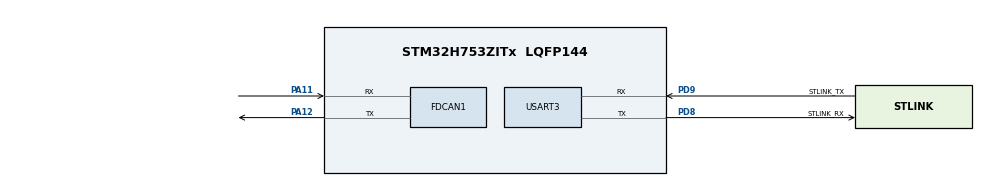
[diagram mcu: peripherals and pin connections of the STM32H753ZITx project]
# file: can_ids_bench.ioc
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CORTEX_M7.CPU_DCache=Enabled
CORTEX_M7.CPU_ICache=Enabled
CORTEX_M7.MPU_Control=MPU_PRIVILEGED_DEFAULT
CORTEX_M7.default_mode_Activation=1
FDCAN1.AutoRetransmission=ENABLE
FDCAN1.CalculateBaudRateNominal=500000
FDCAN1.CalculateTimeBitNominal=2000
FDCAN1.CalculateTimeQuantumNominal=125.0
FDCAN1.Mode=FDCAN_MODE_INTERNAL_LOOPBACK
FDCAN1.NominalPrescaler=1
FDCAN1.NominalSyncJumpWidth=2
FDCAN1.NominalTimeSeg1=13
FDCAN1.NominalTimeSeg2=2
FDCAN1.RxFifo0ElmtsNbr=32
FDCAN1.TxFifoQueueElmtsNbr=8
FDCAN1.TxFifoQueueMode=FDCAN_TX_QUEUE_OPERATION
FREERTOS.Tasks01=defaultTask,24,128,StartDefaultTask,Default,NULL,Dynamic,NULL,NULL
FREERTOS.configTOTAL_HEAP_SIZE=65536
FREERTOS.configUSE_NEWLIB_REENTRANT=1
Mcu.Family=STM32H7
Mcu.Name=STM32H753ZITx
Mcu.Package=LQFP144
NVIC.FDCAN1_IT0_IRQn=true\:5\:0\:true\:false\:true\:true\:true\:true\:true
NVIC.PriorityGroup=NVIC_PRIORITYGROUP_4
NVIC.TIM6_DAC_IRQn=true\:15\:0\:false\:false\:true\:false\:false\:true\:true
NVIC.TIM7_IRQn=true\:5\:0\:false\:false\:true\:true\:true\:true\:true
NVIC.TimeBase=TIM6_DAC_IRQn
NVIC.TimeBaseIP=TIM6
PA11.Mode=FDCAN_Activate
PA11.Signal=FDCAN1_RX
PA12.Mode=FDCAN_Activate
PA12.Signal=FDCAN1_TX
PA13\ (JTMS/SWDIO).Mode=Serial_Wire
PA13\ (JTMS/SWDIO).Signal=DEBUG_JTMS-SWDIO
PA14\ (JTCK/SWCLK).Mode=Serial_Wire
PA14\ (JTCK/SWCLK).Signal=DEBUG_JTCK-SWCLK
PC14-OSC32_IN\ (OSC32_IN).Signal=RCC_OSC32_IN
PC15-OSC32_OUT\ (OSC32_OUT).Signal=RCC_OSC32_OUT
PD8.GPIO_Label=STLINK_RX
PD8.Mode=Asynchronous
PD8.Signal=USART3_TX
PD9.GPIO_Label=STLINK_TX
PD9.Mode=Asynchronous
PD9.Signal=USART3_RX
PH0-OSC_IN\ (PH0).Mode=HSE-External-Clock-Source
PH0-OSC_IN\ (PH0).Signal=RCC_OSC_IN
PH1-OSC_OUT\ (PH1).Signal=RCC_OSC_OUT
ProjectManager.HeapSize=0x1000
ProjectManager.StackSize=0x2000
ProjectManager.TargetToolchain=STM32CubeIDE
RCC.ADCFreq_Value=16125000
RCC.APB1Freq_Value=120000000
RCC.APB2Freq_Value=120000000
RCC.APB3Freq_Value=120000000
RCC.APB4Freq_Value=120000000
RCC.CortexFreq_Value=480000000
RCC.D1PPRE=RCC_APB3_DIV2
RCC.D2PPRE1=RCC_APB1_DIV2
RCC.D2PPRE2=RCC_APB2_DIV2
RCC.D3PPRE=RCC_APB4_DIV2
RCC.DIVM1=1
RCC.DIVN1=120
RCC.DIVQ1=4
RCC.FDCANCLockSelection=RCC_FDCANCLKSOURCE_HSE
RCC.HCLKFreq_Value=240000000
RCC.HPRE=RCC_HCLK_DIV2
RCC.HSE_VALUE=8000000
RCC.PLLFRACN=0
RCC.PLLSourceVirtual=RCC_PLLSOURCE_HSE
RCC.PWR_Regulator_Voltage_Scale=PWR_REGULATOR_VOLTAGE_SCALE0
RCC.SYSCLKFreq_VALUE=480000000
RCC.SYSCLKSource=RCC_SYSCLKSOURCE_PLLCLK
RCC.USBFreq_Value=240000000
TIM7.Period=49
TIM7.Prescaler=239
USART3.VirtualMode-Asynchronous=VM_ASYNC
VP_FREERTOS_VS_CMSIS_V2.Mode=CMSIS_V2
VP_MEMORYMAP_VS_MEMORYMAP.Mode=CurAppReg
VP_SYS_VS_tim6.Mode=TIM6
VP_TIM7_VS_ClockSourceINT.Mode=Enable_Timer
board=NUCLEO-H753ZI

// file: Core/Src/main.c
/* USER CODE BEGIN Header */
/**
  ******************************************************************************
  * @file           : main.c
  * @brief          : Main program body
  ******************************************************************************
  * @attention
  *
  * Copyright (c) 2026 STMicroelectronics.
  * All rights reserved.
  *
  * This software is licensed under terms that can be found in the LICENSE file
  * in the root directory of this software component.
  * If no LICENSE file comes with this software, it is provided AS-IS.
  *
  ******************************************************************************
  */
/* USER CODE END Header */
#include "main.h"
#include "FreeRTOS.h"
#include "cmsis_os2.h"

/* USER CODE BEGIN Includes */
#include "ids_bench.h"   // declares ids_bench_run()
#include "ids_demo.h"
/* USER CODE END Includes */

FDCAN_HandleTypeDef hfdcan1;

TIM_HandleTypeDef htim7;

UART_HandleTypeDef huart3;

/* Definitions for defaultTask */
osThreadId_t defaultTaskHandle;
const osThreadAttr_t defaultTask_attributes = {
  .name = "defaultTask",
  .stack_size = 128 * 4,
  .priority = (osPriority_t) osPriorityNormal,
};
/* USER CODE BEGIN PV */
volatile uint32_t dbg_tim7_ticks = 0;

/* USER CODE END PV */

void SystemClock_Config(void);
static void MPU_Config(void);
static void MX_GPIO_Init(void);
static void MX_FDCAN1_Init(void);
static void MX_TIM7_Init(void);
static void MX_USART3_UART_Init(void);
void StartDefaultTask(void *argument);

int main(void)
{

  /* MPU Configuration--------------------------------------------------------*/
  MPU_Config();

  /* Enable the CPU Cache */

  /* Enable I-Cache---------------------------------------------------------*/
  SCB_EnableICache();

  /* Enable D-Cache---------------------------------------------------------*/
  SCB_EnableDCache();

  /* MCU Configuration--------------------------------------------------------*/

  /* Reset of all peripherals, Initializes the Flash interface and the Systick. */
  HAL_Init();

  /* Configure the system clock */
  SystemClock_Config();

  /* Initialize all configured peripherals */
  MX_GPIO_Init();
  MX_FDCAN1_Init();
  MX_TIM7_Init();
  MX_USART3_UART_Init();
  /* USER CODE BEGIN 2 */

  // Runs the benchmark once (~1 min) before FreeRTOS starts.
  // hfdcan1 = FDCAN1 handle (internal loopback, 500 kbit/s), huart3 = UART to the ST-LINK USB serial port

 ids_bench_run(&hfdcan1, &huart3);
  /* USER CODE END 2 */

  /* Init scheduler */
  osKernelInitialize();

  /* Create the thread(s) */
  /* creation of defaultTask */
  defaultTaskHandle = osThreadNew(StartDefaultTask, NULL, &defaultTask_attributes);

  /* USER CODE BEGIN RTOS_THREADS */
  /* add threads, ... */
  //ids_demo_start(&hfdcan1, &huart3, &htim7);
  /* USER CODE END RTOS_THREADS */

  /* Start scheduler */
  osKernelStart();

  /* We should never get here as control is now taken by the scheduler */

  /* Infinite loop */
  while (1)
  {

  }
}

void SystemClock_Config(void)
{
  RCC_OscInitTypeDef RCC_OscInitStruct = {0};
  RCC_ClkInitTypeDef RCC_ClkInitStruct = {0};

  /** Supply configuration update enable
  */
  HAL_PWREx_ConfigSupply(PWR_LDO_SUPPLY);

  /** Configure the main internal regulator output voltage
  */
  __HAL_PWR_VOLTAGESCALING_CONFIG(PWR_REGULATOR_VOLTAGE_SCALE0);

  while(!__HAL_PWR_GET_FLAG(PWR_FLAG_VOSRDY)) {}

  /** Initializes the RCC Oscillators according to the specified parameters
  * in the RCC_OscInitTypeDef structure.
  */
  RCC_OscInitStruct.OscillatorType = RCC_OSCILLATORTYPE_HSE;
  RCC_OscInitStruct.HSEState = RCC_HSE_BYPASS;
  RCC_OscInitStruct.PLL.PLLState = RCC_PLL_ON;
  RCC_OscInitStruct.PLL.PLLSource = RCC_PLLSOURCE_HSE;
  RCC_OscInitStruct.PLL.PLLM = 1;
  RCC_OscInitStruct.PLL.PLLN = 120;
  RCC_OscInitStruct.PLL.PLLP = 2;
  RCC_OscInitStruct.PLL.PLLQ = 4;
  RCC_OscInitStruct.PLL.PLLR = 2;
  RCC_OscInitStruct.PLL.PLLRGE = RCC_PLL1VCIRANGE_3;
  RCC_OscInitStruct.PLL.PLLVCOSEL = RCC_PLL1VCOWIDE;
  RCC_OscInitStruct.PLL.PLLFRACN = 0;
  if (HAL_RCC_OscConfig(&RCC_OscInitStruct) != HAL_OK)
  {
    Error_Handler();
  }

  /** Initializes the CPU, AHB and APB buses clocks
  */
  RCC_ClkInitStruct.ClockType = RCC_CLOCKTYPE_HCLK|RCC_CLOCKTYPE_SYSCLK
                              |RCC_CLOCKTYPE_PCLK1|RCC_CLOCKTYPE_PCLK2
                              |RCC_CLOCKTYPE_D3PCLK1|RCC_CLOCKTYPE_D1PCLK1;
  RCC_ClkInitStruct.SYSCLKSource = RCC_SYSCLKSOURCE_PLLCLK;
  RCC_ClkInitStruct.SYSCLKDivider = RCC_SYSCLK_DIV1;
  RCC_ClkInitStruct.AHBCLKDivider = RCC_HCLK_DIV2;
  RCC_ClkInitStruct.APB3CLKDivider = RCC_APB3_DIV2;
  RCC_ClkInitStruct.APB1CLKDivider = RCC_APB1_DIV2;
  RCC_ClkInitStruct.APB2CLKDivider = RCC_APB2_DIV2;
  RCC_ClkInitStruct.APB4CLKDivider = RCC_APB4_DIV2;

  if (HAL_RCC_ClockConfig(&RCC_ClkInitStruct, FLASH_LATENCY_4) != HAL_OK)
  {
    Error_Handler();
  }
}

static void MX_FDCAN1_Init(void)
{

  hfdcan1.Instance = FDCAN1;
  hfdcan1.Init.FrameFormat = FDCAN_FRAME_CLASSIC;
  hfdcan1.Init.Mode = FDCAN_MODE_INTERNAL_LOOPBACK;
  hfdcan1.Init.AutoRetransmission = ENABLE;
  hfdcan1.Init.TransmitPause = DISABLE;
  hfdcan1.Init.ProtocolException = DISABLE;
  hfdcan1.Init.NominalPrescaler = 1;
  hfdcan1.Init.NominalSyncJumpWidth = 2;
  hfdcan1.Init.NominalTimeSeg1 = 13;
  hfdcan1.Init.NominalTimeSeg2 = 2;
  hfdcan1.Init.DataPrescaler = 1;
  hfdcan1.Init.DataSyncJumpWidth = 1;
  hfdcan1.Init.DataTimeSeg1 = 1;
  hfdcan1.Init.DataTimeSeg2 = 1;
  hfdcan1.Init.MessageRAMOffset = 0;
  hfdcan1.Init.StdFiltersNbr = 0;
  hfdcan1.Init.ExtFiltersNbr = 0;
  hfdcan1.Init.RxFifo0ElmtsNbr = 32;
  hfdcan1.Init.RxFifo0ElmtSize = FDCAN_DATA_BYTES_8;
  hfdcan1.Init.RxFifo1ElmtsNbr = 0;
  hfdcan1.Init.RxFifo1ElmtSize = FDCAN_DATA_BYTES_8;
  hfdcan1.Init.RxBuffersNbr = 0;
  hfdcan1.Init.RxBufferSize = FDCAN_DATA_BYTES_8;
  hfdcan1.Init.TxEventsNbr = 0;
  hfdcan1.Init.TxBuffersNbr = 0;
  hfdcan1.Init.TxFifoQueueElmtsNbr = 8;
  hfdcan1.Init.TxFifoQueueMode = FDCAN_TX_QUEUE_OPERATION;
  hfdcan1.Init.TxElmtSize = FDCAN_DATA_BYTES_8;
  if (HAL_FDCAN_Init(&hfdcan1) != HAL_OK)
  {
    Error_Handler();
  }

}

static void MX_TIM7_Init(void)
{

  TIM_MasterConfigTypeDef sMasterConfig = {0};

  htim7.Instance = TIM7;
  htim7.Init.Prescaler = 239;
  htim7.Init.CounterMode = TIM_COUNTERMODE_UP;
  htim7.Init.Period = 49;
  htim7.Init.AutoReloadPreload = TIM_AUTORELOAD_PRELOAD_DISABLE;
  if (HAL_TIM_Base_Init(&htim7) != HAL_OK)
  {
    Error_Handler();
  }
  sMasterConfig.MasterOutputTrigger = TIM_TRGO_RESET;
  sMasterConfig.MasterSlaveMode = TIM_MASTERSLAVEMODE_DISABLE;
  if (HAL_TIMEx_MasterConfigSynchronization(&htim7, &sMasterConfig) != HAL_OK)
  {
    Error_Handler();
  }

}

static void MX_USART3_UART_Init(void)
{

  huart3.Instance = USART3;
  huart3.Init.BaudRate = 115200;
  huart3.Init.WordLength = UART_WORDLENGTH_8B;
  huart3.Init.StopBits = UART_STOPBITS_1;
  huart3.Init.Parity = UART_PARITY_NONE;
  huart3.Init.Mode = UART_MODE_TX_RX;
  huart3.Init.HwFlowCtl = UART_HWCONTROL_NONE;
  huart3.Init.OverSampling = UART_OVERSAMPLING_16;
  huart3.Init.OneBitSampling = UART_ONE_BIT_SAMPLE_DISABLE;
  huart3.Init.ClockPrescaler = UART_PRESCALER_DIV1;
  huart3.AdvancedInit.AdvFeatureInit = UART_ADVFEATURE_NO_INIT;
  if (HAL_UART_Init(&huart3) != HAL_OK)
  {
    Error_Handler();
  }
  if (HAL_UARTEx_SetTxFifoThreshold(&huart3, UART_TXFIFO_THRESHOLD_1_8) != HAL_OK)
  {
    Error_Handler();
  }
  if (HAL_UARTEx_SetRxFifoThreshold(&huart3, UART_RXFIFO_THRESHOLD_1_8) != HAL_OK)
  {
    Error_Handler();
  }
  if (HAL_UARTEx_DisableFifoMode(&huart3) != HAL_OK)
  {
    Error_Handler();
  }

}

static void MX_GPIO_Init(void)
{

  /* GPIO Ports Clock Enable */
  __HAL_RCC_GPIOC_CLK_ENABLE();
  __HAL_RCC_GPIOH_CLK_ENABLE();
  __HAL_RCC_GPIOD_CLK_ENABLE();
  __HAL_RCC_GPIOA_CLK_ENABLE();

}

void StartDefaultTask(void *argument)
{
  for(;;)
  {
    osDelay(1);
  }
}

 /* MPU Configuration */

void MPU_Config(void)
{
  MPU_Region_InitTypeDef MPU_InitStruct = {0};

  /* Disables the MPU */
  HAL_MPU_Disable();

  /** Initializes and configures the Region and the memory to be protected
  */
  MPU_InitStruct.Enable = MPU_REGION_ENABLE;
  MPU_InitStruct.Number = MPU_REGION_NUMBER0;
  MPU_InitStruct.BaseAddress = 0x0;
  MPU_InitStruct.Size = MPU_REGION_SIZE_4GB;
  MPU_InitStruct.SubRegionDisable = 0x87;
  MPU_InitStruct.TypeExtField = MPU_TEX_LEVEL0;
  MPU_InitStruct.AccessPermission = MPU_REGION_NO_ACCESS;
  MPU_InitStruct.DisableExec = MPU_INSTRUCTION_ACCESS_DISABLE;
  MPU_InitStruct.IsShareable = MPU_ACCESS_SHAREABLE;
  MPU_InitStruct.IsCacheable = MPU_ACCESS_NOT_CACHEABLE;
  MPU_InitStruct.IsBufferable = MPU_ACCESS_NOT_BUFFERABLE;

  HAL_MPU_ConfigRegion(&MPU_InitStruct);
  /* Enables the MPU */
  HAL_MPU_Enable(MPU_PRIVILEGED_DEFAULT);

}

void HAL_TIM_PeriodElapsedCallback(TIM_HandleTypeDef *htim)
{
  /* USER CODE BEGIN Callback 0 */

	if (htim->Instance == TIM7) { ids_demo_tick(); return; }

  /* USER CODE END Callback 0 */
  if (htim->Instance == TIM6)
  {
    HAL_IncTick();
  }
}

void Error_Handler(void)
{
  __disable_irq();
  while (1)
  {
  }
}
